AUTOSAR XML (schema 314)
package /ComponentType
  internal behavior Sa_MtrVel2_InternalBehavior: component=Sa_MtrVel2
    timing event MtrVel2_InitEvent: start-on-event=MtrVel2_Init, period=0
    timing event TMT_MtrVel2_Per1: start-on-event=MtrVel2_Per1, period=0.002
    timing event TMT_MtrVel2_Per2: start-on-event=MtrVel2_Per2, period=0.002
    port-api-options:
      enable-take-address=false, indirect-api=false, port=AsstAssemblyPolarity
      enable-take-address=false, indirect-api=false, port=CumMechMtrPosMRF
      enable-take-address=false, indirect-api=false, port=HandwheelVel
      enable-take-address=false, indirect-api=false, port=MechMtrPos1Timestamp
      enable-take-address=false, indirect-api=false, port=MotorVelMRF
      enable-take-address=false, indirect-api=false, port=NxtrDiagMgr
      enable-take-address=false, indirect-api=false, port=SysCDiagHwVel
      enable-take-address=false, indirect-api=false, port=SysCDiagMtrVelMRF
    runnable MtrVel2_Init
      data read access READ_CumMechMtrPosMRF_Deg_f32: data-element=CumMechMtrPosMRF.Deg_f32
    runnable MtrVel2_Per1
      data read access READ_AsstAssemblyPolarity_Cnt_s08: data-element=AsstAssemblyPolarity.Cnt_s08
      data read access READ_CumMechMtrPosMRF_Deg_f32: data-element=CumMechMtrPosMRF.Deg_f32
      data read access READ_MechMtrPos1Timestamp_USec_u32: data-element=MechMtrPos1Timestamp.USec_u32
      data write access WRITE_SysCDiagHwVel_HwRadpS_f32: data-element=SysCDiagHwVel.HwRadpS_f32
      data write access WRITE_SysCDiagMtrVelMRF_MtrRadpS_f32: data-element=SysCDiagMtrVelMRF.MtrRadpS_f32
    runnable MtrVel2_Per2
      data read access READ_HandwheelVel_HwRadpS_f32: data-element=HandwheelVel.HwRadpS_f32
      data read access READ_MotorVelMRF_MtrRadpS_f32: data-element=MotorVelMRF.MtrRadpS_f32
      sync call SC_NxtrDiagMgr_GetNTCFailed: operation=NxtrDiagMgr.GetNTCFailed, timeout=0
      sync call SC_NxtrDiagMgr_SetNTCStatus: operation=NxtrDiagMgr.SetNTCStatus, timeout=0
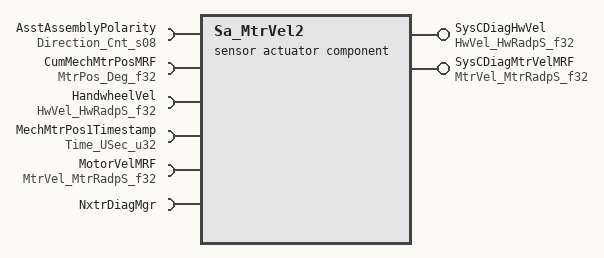
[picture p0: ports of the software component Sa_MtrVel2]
  sensor actuator software component type Sa_MtrVel2
    provide port SysCDiagHwVel: unqueued-sender-com-spec{data-element=HwRadpS_f32, can-invalidate=false, init-value=D_ZERO_ULS_F32}, provided-interface=HwVel_HwRadpS_f32
    provide port SysCDiagMtrVelMRF: unqueued-sender-com-spec{data-element=MtrRadpS_f32, can-invalidate=false, init-value=D_ZERO_ULS_F32}, provided-interface=MtrVel_MtrRadpS_f32
    6 x require port:
      AsstAssemblyPolarity: unqueued-receiver-com-spec{data-element=Cnt_s08, init-value=D_ZERO_CNT_S8}, required-interface=Direction_Cnt_s08
      CumMechMtrPosMRF: unqueued-receiver-com-spec{data-element=Deg_f32, init-value=D_ZERO_ULS_F32}, required-interface=MtrPos_Deg_f32
      HandwheelVel: unqueued-receiver-com-spec{data-element=HwRadpS_f32, init-value=D_ZERO_ULS_F32}, required-interface=HwVel_HwRadpS_f32
      MechMtrPos1Timestamp: unqueued-receiver-com-spec{data-element=USec_u32, init-value=D_ZERO_CNT_U32}, required-interface=Time_USec_u32
      MotorVelMRF: unqueued-receiver-com-spec{data-element=MtrRadpS_f32, init-value=D_ZERO_ULS_F32}, required-interface=MtrVel_MtrRadpS_f32
      NxtrDiagMgr: required-com-specs=[GetNTCActive, GetNTCFailed, GetNTCStatus, SetNTCStatus], required-interface=NxtrDiagMgr
  swc implementation Sa_MtrVel2_Implementation: behavior=Sa_MtrVel2_InternalBehavior
    code-descriptors:
      code Code: type=SRC
